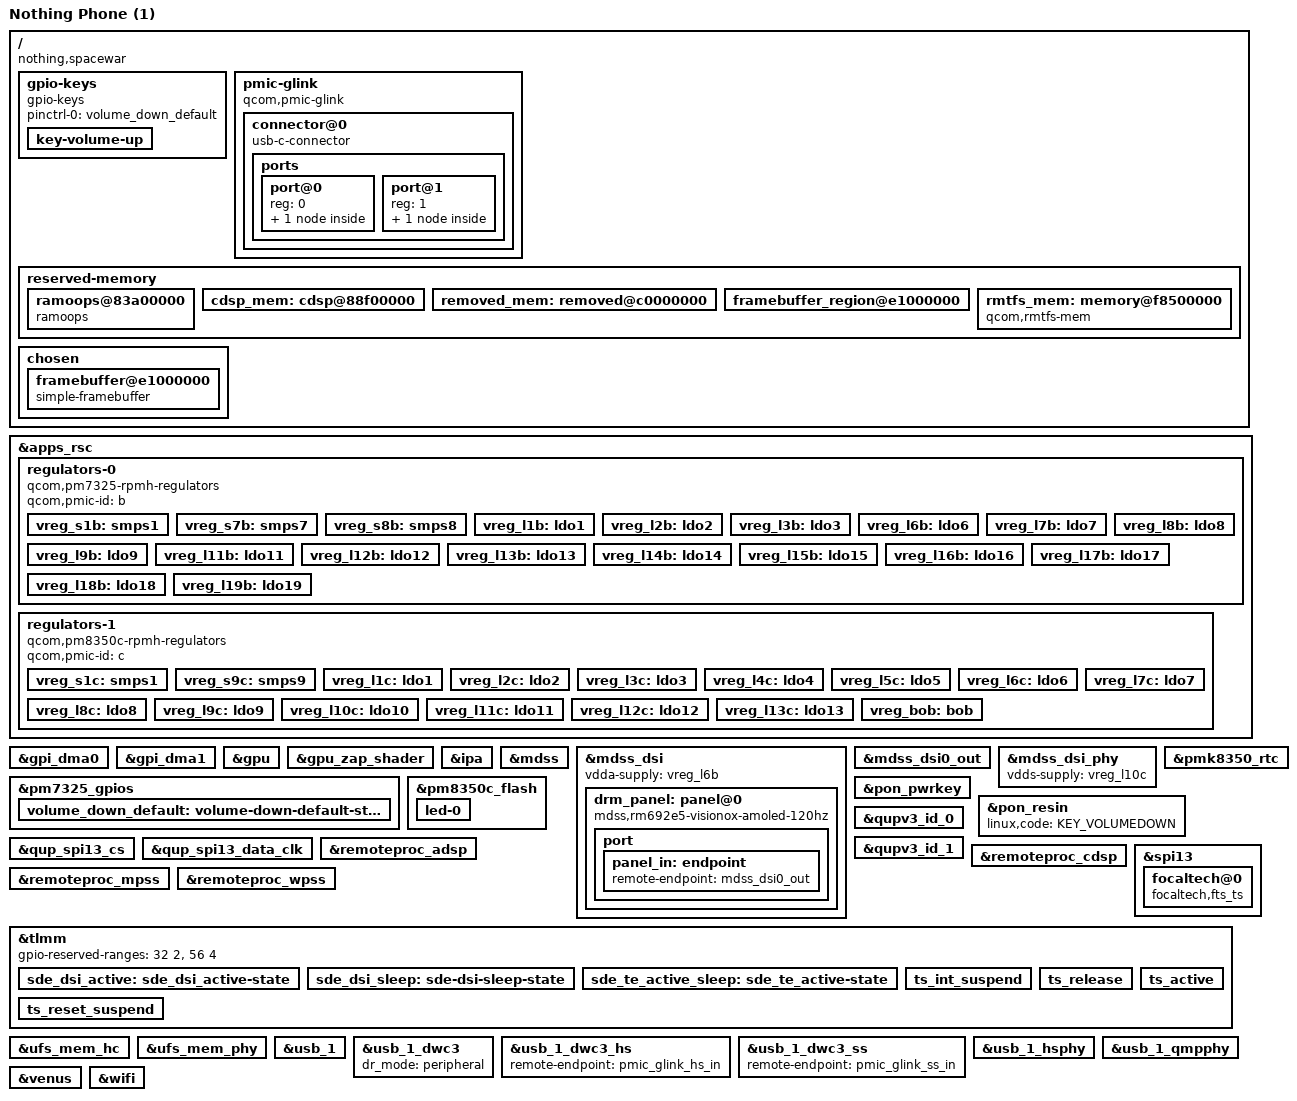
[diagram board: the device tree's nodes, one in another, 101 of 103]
// SPDX-License-Identifier: BSD-3-Clause
/*
 * Copyright (c) 2024, Eugene Lepshy <fekz115@gmail.com>
 */

/dts-v1/;

#define PM7250B_SID 8
#define PM7250B_SID1 9

#include <dt-bindings/gpio/gpio.h>
#include <dt-bindings/regulator/qcom,rpmh-regulator.h>
#include <dt-bindings/leds/common.h>

#include <dt-bindings/iio/qcom,spmi-adc7-pm7325.h>
#include <dt-bindings/iio/qcom,spmi-adc7-pmk8350.h>
#include <dt-bindings/pinctrl/qcom,pmic-gpio.h>
#include "sm7325.dtsi"
#include "pm7250b.dtsi"
#include "pm7325.dtsi"
#include "pm8350c.dtsi" /* PM7350C */
#include "pmk8350.dtsi" /* PMK7325 */

/delete-node/ &rmtfs_mem;

/ {
	model = "Nothing Phone (1)";
	compatible = "nothing,spacewar", "qcom,sm7325";
	qcom,msm-id = <0x1db 0x10000 0x203 0x10000>;
	qcom,board-id = <0x1000b 0x00>;
	chassis-type = "handset";

	gpio-keys {
		compatible = "gpio-keys";

		pinctrl-0 = <&volume_down_default>;
		pinctrl-names = "default";

		key-volume-up {
			label = "Volume up";
			gpios = <&pm7325_gpios 6 GPIO_ACTIVE_LOW>;
			linux,code = <KEY_VOLUMEUP>;
		};
	};

	pmic-glink {
		compatible = "qcom,pmic-glink";

		#address-cells = <1>;
		#size-cells = <0>;

		connector@0 {
			compatible = "usb-c-connector";
			reg = <0>;
			power-role = "dual";
			data-role = "dual";

			ports {
				#address-cells = <1>;
				#size-cells = <0>;

				port@0 {
					reg = <0>;

					pmic_glink_hs_in: endpoint {
						remote-endpoint = <&usb_1_dwc3_hs>;
					};
				};

				port@1 {
					reg = <1>;

					pmic_glink_ss_in: endpoint {
						remote-endpoint = <&usb_1_dwc3_ss>;
					};
				};
			};
		};
	};

	reserved-memory {
		#address-cells = <2>;
		#size-cells = <2>;
		ranges;

		ramoops@83a00000 {
			compatible = "ramoops";
			reg = <0x0 0x83a00000 0x0 0x400000>;
			pmsg-size = <0x200000>;
			mem-type = <0x02>;
			console-size = <0x200000>;
		};

		cdsp_mem: cdsp@88f00000 {
			reg = <0x0 0x88f00000 0x0 0x1e00000>;
			no-map;
		};

		removed_mem: removed@c0000000 {
			reg = <0x0 0xc0000000 0x0 0x5100000>;
			no-map;
		};

		framebuffer_region@e1000000 {
			reg = <0x0 0xe1000000 0x0 (1080 * 2400 * 4)>;
			no-map;
		};

		rmtfs_mem: memory@f8500000 {
			compatible = "qcom,rmtfs-mem";
			reg = <0x0 0xf8500000 0x0 0x600000>;
			no-map;

			qcom,client-id = <1>;
			qcom,vmid = <QCOM_SCM_VMID_MSS_MSA>, <QCOM_SCM_VMID_NAV>;
		};
	};

	chosen {
		#address-cells = <2>;
		#size-cells = <2>;
		ranges;

		framebuffer@e1000000 {
			compatible = "simple-framebuffer";
			reg = <0x0 0xe1000000 0x0 (1080 * 2400 * 4)>;
			width = <1080>;
			height = <2400>;
			stride = <(1080 * 4)>;
			format = "a8r8g8b8";
		};
	};
};

&apps_rsc {
	regulators-0 {
		compatible = "qcom,pm7325-rpmh-regulators";
		qcom,pmic-id = "b";

		vreg_s1b: smps1 {
			regulator-min-microvolt = <1840000>;
			regulator-max-microvolt = <2040000>;
		};

		vreg_s7b: smps7 {
			regulator-min-microvolt = <535000>;
			regulator-max-microvolt = <1120000>;
		};

		vreg_s8b: smps8 {
			regulator-min-microvolt = <1200000>;
			regulator-max-microvolt = <1500000>;
			regulator-initial-mode = <RPMH_REGULATOR_MODE_RET>;
		};

		vreg_l1b: ldo1 {
			regulator-min-microvolt = <825000>;
			regulator-max-microvolt = <925000>;
			regulator-initial-mode = <RPMH_REGULATOR_MODE_HPM>;
		};

		vreg_l2b: ldo2 {
			regulator-min-microvolt = <2700000>;
			regulator-max-microvolt = <3544000>;
			regulator-initial-mode = <RPMH_REGULATOR_MODE_HPM>;
		};

		vreg_l3b: ldo3 {
			regulator-min-microvolt = <312000>;
			regulator-max-microvolt = <910000>;
			regulator-initial-mode = <RPMH_REGULATOR_MODE_HPM>;
		};

		vreg_l6b: ldo6 {
			regulator-min-microvolt = <1140000>;
			regulator-max-microvolt = <1260000>;
			regulator-initial-mode = <RPMH_REGULATOR_MODE_HPM>;
		};

		vreg_l7b: ldo7 {
			regulator-min-microvolt = <2952000>;
			regulator-max-microvolt = <2952000>;
			regulator-initial-mode = <RPMH_REGULATOR_MODE_HPM>;
		};

		vreg_l8b: ldo8 {
			regulator-min-microvolt = <870000>;
			regulator-max-microvolt = <970000>;
			regulator-initial-mode = <RPMH_REGULATOR_MODE_HPM>;
		};

		vreg_l9b: ldo9 {
			regulator-min-microvolt = <1200000>;
			regulator-max-microvolt = <1304000>;
			regulator-initial-mode = <RPMH_REGULATOR_MODE_HPM>;
		};

		vreg_l11b: ldo11 {
			regulator-min-microvolt = <1504000>;
			regulator-max-microvolt = <2000000>;
			regulator-initial-mode = <RPMH_REGULATOR_MODE_HPM>;
		};

		vreg_l12b: ldo12 {
			regulator-min-microvolt = <751000>;
			regulator-max-microvolt = <824000>;
			regulator-initial-mode = <RPMH_REGULATOR_MODE_HPM>;
		};

		vreg_l13b: ldo13 {
			regulator-min-microvolt = <530000>;
			regulator-max-microvolt = <824000>;
			regulator-initial-mode = <RPMH_REGULATOR_MODE_HPM>;
		};

		vreg_l14b: ldo14 {
			regulator-min-microvolt = <1080000>;
			regulator-max-microvolt = <1304000>;
			regulator-initial-mode = <RPMH_REGULATOR_MODE_HPM>;
		};

		vreg_l15b: ldo15 {
			regulator-min-microvolt = <765000>;
			regulator-max-microvolt = <1020000>;
			regulator-initial-mode = <RPMH_REGULATOR_MODE_HPM>;
		};

		vreg_l16b: ldo16 {
			regulator-min-microvolt = <1100000>;
			regulator-max-microvolt = <1300000>;
			regulator-initial-mode = <RPMH_REGULATOR_MODE_HPM>;
		};

		vreg_l17b: ldo17 {
			regulator-min-microvolt = <1700000>;
			regulator-max-microvolt = <1900000>;
			regulator-initial-mode = <RPMH_REGULATOR_MODE_HPM>;
		};

		vreg_l18b: ldo18 {
			regulator-min-microvolt = <1800000>;
			regulator-max-microvolt = <2000000>;
			regulator-initial-mode = <RPMH_REGULATOR_MODE_HPM>;
		};

		vreg_l19b: ldo19 {
			regulator-min-microvolt = <1800000>;
			regulator-max-microvolt = <2000000>;
			regulator-initial-mode = <RPMH_REGULATOR_MODE_HPM>;
		};
	};

	regulators-1 {
		compatible = "qcom,pm8350c-rpmh-regulators";
		qcom,pmic-id = "c";

		vreg_s1c: smps1 {
			regulator-min-microvolt = <2190000>;
			regulator-max-microvolt = <2210000>;
		};

		vreg_s9c: smps9 {
			regulator-min-microvolt = <1010000>;
			regulator-max-microvolt = <1170000>;
		};

		vreg_l1c: ldo1 {
			regulator-min-microvolt = <1800000>;
			regulator-max-microvolt = <1980000>;
			regulator-initial-mode = <RPMH_REGULATOR_MODE_HPM>;
		};

		vreg_l2c: ldo2 {
			regulator-min-microvolt = <1620000>;
			regulator-max-microvolt = <1980000>;
			regulator-initial-mode = <RPMH_REGULATOR_MODE_HPM>;
		};

		vreg_l3c: ldo3 {
			regulator-min-microvolt = <2800000>;
			regulator-max-microvolt = <3540000>;
			regulator-initial-mode = <RPMH_REGULATOR_MODE_HPM>;
			regulator-always-on;
		};

		vreg_l4c: ldo4 {
			regulator-min-microvolt = <1620000>;
			regulator-max-microvolt = <3300000>;
			regulator-initial-mode = <RPMH_REGULATOR_MODE_HPM>;
		};

		vreg_l5c: ldo5 {
			regulator-min-microvolt = <1620000>;
			regulator-max-microvolt = <3300000>;
			regulator-initial-mode = <RPMH_REGULATOR_MODE_HPM>;
		};

		vreg_l6c: ldo6 {
			regulator-min-microvolt = <1650000>;
			regulator-max-microvolt = <3544000>;
			regulator-initial-mode = <RPMH_REGULATOR_MODE_HPM>;
		};

		vreg_l7c: ldo7 {
			regulator-min-microvolt = <3000000>;
			regulator-max-microvolt = <3544000>;
			regulator-initial-mode = <RPMH_REGULATOR_MODE_HPM>;
		};

		vreg_l8c: ldo8 {
			regulator-min-microvolt = <1620000>;
			regulator-max-microvolt = <2000000>;
			regulator-initial-mode = <RPMH_REGULATOR_MODE_HPM>;
			regulator-always-on;
		};

		vreg_l9c: ldo9 {
			regulator-min-microvolt = <2700000>;
			regulator-max-microvolt = <3544000>;
			regulator-initial-mode = <RPMH_REGULATOR_MODE_HPM>;
		};

		vreg_l10c: ldo10 {
			regulator-min-microvolt = <720000>;
			regulator-max-microvolt = <1050000>;
			regulator-initial-mode = <RPMH_REGULATOR_MODE_HPM>;
		};

		vreg_l11c: ldo11 {
			regulator-min-microvolt = <2800000>;
			regulator-max-microvolt = <3544000>;
			regulator-initial-mode = <RPMH_REGULATOR_MODE_HPM>;
		};

		vreg_l12c: ldo12 {
			regulator-min-microvolt = <1650000>;
			regulator-max-microvolt = <2000000>;
			regulator-initial-mode = <RPMH_REGULATOR_MODE_HPM>;
		};

		vreg_l13c: ldo13 {
			regulator-min-microvolt = <2700000>;
			regulator-max-microvolt = <3544000>;
			regulator-initial-mode = <RPMH_REGULATOR_MODE_HPM>;
		};

		vreg_bob: bob {
			regulator-min-microvolt = <3008000>;
			regulator-max-microvolt = <3960000>;
		};
	};
};

&gpi_dma0 {
	status = "okay";
};

&gpi_dma1 {
	status = "okay";
};

&gpu {
	status = "okay";
};

&gpu_zap_shader {
	firmware-name = "qcom/sm7325/nothing-spacewar/a660_zap.mbn";
};

&ipa {
	qcom,gsi-loader = "self";
	memory-region = <&ipa_fw_mem>;
	firmware-name = "qcom/sm7325/nothing-spacewar/ipa_fws.mbn";
	status = "okay";
};

&mdss {
	status = "okay";
};

&mdss_dsi {
	vdda-supply = <&vreg_l6b>;
	status = "okay";

	drm_panel: panel@0 {
		compatible = "mdss,rm692e5-visionox-amoled-120hz";
		reg = <0>;

		reset-gpios = <&tlmm 44 GPIO_ACTIVE_LOW>;

		//vci-supply = <&vreg_oled_vci>;
		vddio-supply = <&vreg_l12c>;
		//dvdd-supply = <&vreg_oled_dvdd>;

		pinctrl-0 = <&sde_dsi_active &sde_te_active_sleep>;
		pinctrl-1 = <&sde_dsi_sleep &sde_te_active_sleep>;
		pinctrl-names = "default", "sleep";

		port {
			panel_in: endpoint {
				remote-endpoint = <&mdss_dsi0_out>;
			};
		};
	};
};

&mdss_dsi0_out {
	data-lanes = <0 1 2 3>;
	remote-endpoint = <&panel_in>;
};

&mdss_dsi_phy {
	vdds-supply = <&vreg_l10c>;
	status = "okay";
};

&pm7325_gpios {
	volume_down_default: volume-down-default-state {
		pins = "gpio6";
		function = PMIC_GPIO_FUNC_NORMAL;
		power-source = <1>;
		bias-pull-up;
		input-enable;
	};
};

&pm8350c_flash {
	status = "okay";

	led-0 {
		function = LED_FUNCTION_FLASH;
		color = <LED_COLOR_ID_WHITE>;
		led-sources = <1>, <4>;
		led-max-microamp = <500000>;
		flash-max-microamp = <1500000>;
		flash-max-timeout-us = <1280000>;
	};
};

&pmk8350_rtc {
	status = "okay";
};

&pon_pwrkey {
	status = "okay";
};

&pon_resin {
	linux,code = <KEY_VOLUMEDOWN>;
	status = "okay";
};

&qup_spi13_cs {
	drive-strength = <6>;
	bias-disable;
};

&qup_spi13_data_clk {
	drive-strength = <6>;
	bias-disable;
};

&qupv3_id_0 {
	status = "okay";
};

&qupv3_id_1 {
	status = "okay";
};

&remoteproc_adsp {
	firmware-name = "qcom/sm7325/nothing-spacewar/adsp.mbn";
	status = "okay";
};

&remoteproc_cdsp {
	firmware-name = "qcom/sm7325/nothing-spacewar/cdsp.mbn";
	status = "okay";
};

&remoteproc_mpss {
	firmware-name = "qcom/sm7325/nothing-spacewar/modem.mbn";
	status = "okay";
};

&remoteproc_wpss {
	firmware-name = "qcom/sm7325/nothing-spacewar/wpss.mbn";
	status = "okay";
};

&spi13 {
	status = "okay";

	focaltech@0 {
		status = "okay";
		compatible = "focaltech,fts_ts";
		reg = <0x0>;
		spi-max-frequency = <6000000>;
		interrupt-parent = <&tlmm>;
		interrupts = <81 0x2008>;
		focaltech,reset-gpio = <&tlmm 105 0x00>;
		focaltech,irq-gpio = <&tlmm 81 0x2008>;
		focaltech,display-coords = <0 0 1080 2400>;
		focaltech,max-touch-number = <10>;
		focaltech,ic-type = <0x3658D488>;

		vdd-supply = <&vreg_l3c>;
		iovdd-supply = <&vreg_l8c>;

		pinctrl-names = "pmx_ts_active", "pmx_ts_suspend","pmx_ts_release";
		pinctrl-0 = <&ts_active>;
		pinctrl-1 = <&ts_int_suspend &ts_reset_suspend>;
		pinctrl-2 = <&ts_release>;
		focaltech,trusted-touch-mode = "vm_mode";
		focaltech,touch-environment = "pvm";
		focaltech,trusted-touch-spi-irq = <601>;
		focaltech,trusted-touch-io-bases = <0xf134000 0xf135000 0xf136000 0xf137000 0xf169000 0xf151000 0xa94000 0x00a10000>;
		focaltech,trusted-touch-io-sizes = <0x1000 0x1000 0x1000 0x1000 0x1000 0x1000 0x1000 0x4000>;
		//panel = <&drm_panel>;
	};
};


&tlmm {
	/*
	 * 32-33: SMB1394 (SPMI)
	 * 56-59: fingerprint reader (SPI)
	 */
	gpio-reserved-ranges = <32 2>, <56 4>;

	sde_dsi_active: sde_dsi_active-state {
		pins = "gpio44";
		function = "gpio";
		drive-strength = <8>;
		bias-disable;
	};

	sde_dsi_sleep: sde-dsi-sleep-state {
		pins = "gpio44";
		function = "gpio";
		drive-strength = <2>;
		bias-pull-down;
	};

	sde_te_active_sleep: sde_te_active-state {
		pins = "gpio80";
		function = "mdp_vsync";
		drive-strength = <2>;
		bias-pull-down;
	};

	ts_int_suspend: ts_int_suspend {
		pins = "gpio81";
		function = "gpio";
		drive-strength = <2>;
		bias-pull-down;
	};

	ts_release: ts_release {
		pins = "gpio105", "gpio81";
		function = "gpio";
		drive-strength = <2>;
		bias-disable;
	};

	ts_reset_suspend: ts_reset_suspend {
		pins = "gpio105";
		function = "gpio";
		drive-strength = <2>;
		bias-pull-down;
	};

	ts_active: ts_active {
		pins = "gpio105", "gpio81";
		function = "gpio";
		drive-strength = <8>;
		bias-pull-up;
	};

};

&ufs_mem_hc {
	reset-gpios = <&tlmm 175 GPIO_ACTIVE_LOW>;

	vcc-supply = <&vreg_l7b>;
	vcc-max-microamp = <800000>;
	/*
	 * Technically l9b enables an eLDO (supplied by s1b) which then powers
	 * VCCQ2 of the UFS.
	 */
	vccq-supply = <&vreg_l9b>;
	vccq-max-microamp = <900000>;

	status = "okay";
};

&ufs_mem_phy {
	vdda-phy-supply = <&vreg_l10c>;
	vdda-pll-supply = <&vreg_l6b>;
	vdda-phy-max-microamp = <97500>;
	vdda-pll-max-microamp = <18400>;

	status = "okay";
};

&usb_1 {
	status = "okay";
};

&usb_1_dwc3 {
	dr_mode = "peripheral";
};

&usb_1_dwc3_hs {
	remote-endpoint = <&pmic_glink_hs_in>;
};

&usb_1_dwc3_ss {
	remote-endpoint = <&pmic_glink_ss_in>;
};

&usb_1_hsphy {
	status = "okay";
	vdda-pll-supply = <&vreg_l10c>;
	vdda18-supply = <&vreg_l1c>;
	vdda33-supply = <&vreg_l2b>;
};

&usb_1_qmpphy {
	status = "okay";
	vdda-phy-supply = <&vreg_l6b>;
	vdda-pll-supply = <&vreg_l1b>;
};

&venus {
	firmware-name = "qcom/sm7325/nothing-spacewar/venus.mbn";
	status = "okay";
};

&wifi {
	status = "okay";
};
